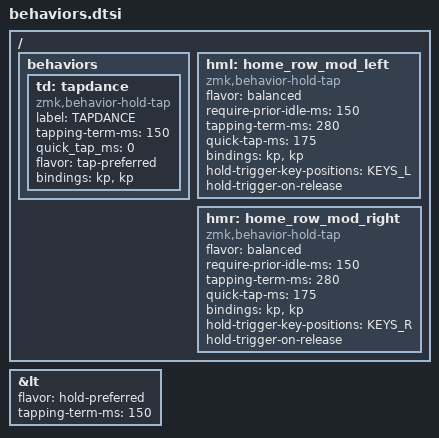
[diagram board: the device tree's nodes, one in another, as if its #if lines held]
#define HOLD_TAP(NAME, FLAVOR, TERM, ...) \
  NAME: NAME##_hold_tap { \
      compatible      = "zmk,behavior-hold-tap"; \
      #binding-cells  = <2>; \
      tapping-term-ms = <TERM>; \
      quick-tap-ms    = <0>; \
      flavor          = #FLAVOR; \
      bindings        = <&kp>, <&kp>; \
      __VA_ARGS__ \
  };

&lt {
    flavor = "hold-preferred";
    tapping-term-ms = <150>;
};

/ {
  behaviors {
    HOLD_TAP(hm_o, tap-preferred, 150)
    HOLD_TAP(hm_m, tap-preferred, 140)
    HOLD_TAP(hm_i, tap-preferred, 130)

   td: tapdance {
      compatible = "zmk,behavior-hold-tap";
      label = "TAPDANCE";
      #binding-cells = <2>;
      tapping-term-ms = <150>;
      quick_tap_ms = <0>;
      flavor = "tap-preferred";
      bindings = <&kp>, <&kp>;
    };
  };

  #ifdef BERYLLINE
  hml: home_row_mod_left {
      compatible = "zmk,behavior-hold-tap";
      #binding-cells = <2>;
      flavor = "balanced";
      require-prior-idle-ms = <150>;
      tapping-term-ms = <280>;
      quick-tap-ms = <175>;
      bindings = <&kp>, <&kp>;
      hold-trigger-key-positions = < KEYS_L >;
      hold-trigger-on-release;
  };
  hmr: home_row_mod_right {
      compatible = "zmk,behavior-hold-tap";
      #binding-cells = <2>;
      flavor = "balanced";
      require-prior-idle-ms = <150>;
      tapping-term-ms = <280>;
      quick-tap-ms = <175>;
      bindings = <&kp>, <&kp>;
      hold-trigger-key-positions = < KEYS_R >;
      hold-trigger-on-release;
  };
  #endif
};

